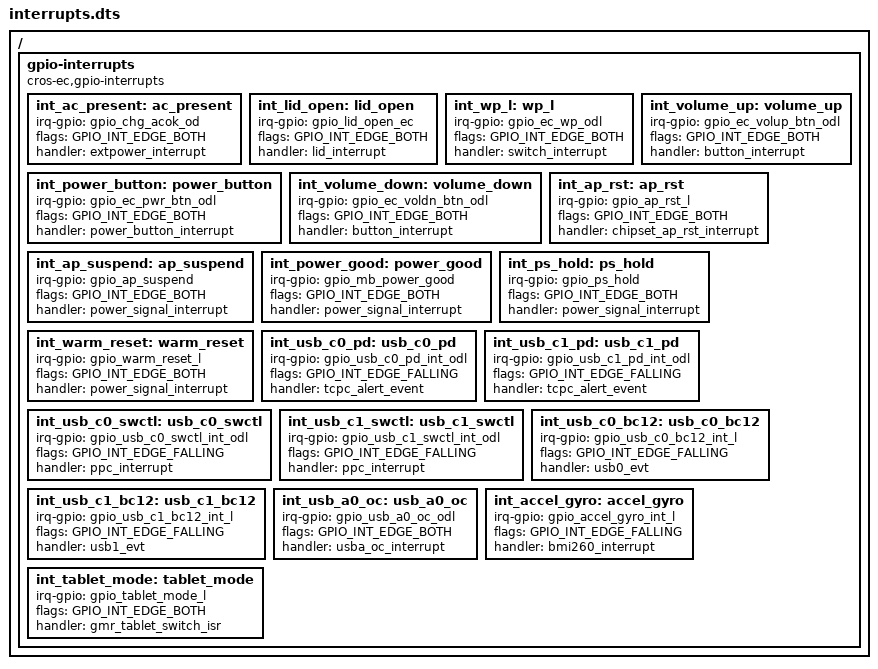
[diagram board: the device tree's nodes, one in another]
/* Copyright 2022 The Chromium OS Authors. All rights reserved.
 * Use of this source code is governed by a BSD-style license that can be
 * found in the LICENSE file.
 */

/ {
	gpio-interrupts {
		compatible = "cros-ec,gpio-interrupts";

		int_ac_present: ac_present {
			irq-gpio = <&gpio_chg_acok_od>;
			flags = <GPIO_INT_EDGE_BOTH>;
			handler = "extpower_interrupt";
		};
		int_lid_open: lid_open {
			irq-gpio = <&gpio_lid_open_ec>;
			flags = <GPIO_INT_EDGE_BOTH>;
			handler = "lid_interrupt";
		};
		int_wp_l: wp_l {
			irq-gpio = <&gpio_ec_wp_odl>;
			flags = <GPIO_INT_EDGE_BOTH>;
			handler = "switch_interrupt";
		};
		int_power_button: power_button {
			irq-gpio = <&gpio_ec_pwr_btn_odl>;
			flags = <GPIO_INT_EDGE_BOTH>;
			handler = "power_button_interrupt";
		};
		int_volume_up: volume_up {
			irq-gpio = <&gpio_ec_volup_btn_odl>;
			flags = <GPIO_INT_EDGE_BOTH>;
			handler = "button_interrupt";
		};
		int_volume_down: volume_down {
			irq-gpio = <&gpio_ec_voldn_btn_odl>;
			flags = <GPIO_INT_EDGE_BOTH>;
			handler = "button_interrupt";
		};
		int_ap_rst: ap_rst {
			irq-gpio = <&gpio_ap_rst_l>;
			flags = <GPIO_INT_EDGE_BOTH>;
			handler = "chipset_ap_rst_interrupt";
		};
		int_ap_suspend: ap_suspend {
			irq-gpio = <&gpio_ap_suspend>;
			flags = <GPIO_INT_EDGE_BOTH>;
			handler = "power_signal_interrupt";
		};
		int_power_good: power_good {
			irq-gpio = <&gpio_mb_power_good>;
			flags = <GPIO_INT_EDGE_BOTH>;
			handler = "power_signal_interrupt";
		};
		int_ps_hold: ps_hold {
			irq-gpio = <&gpio_ps_hold>;
			flags = <GPIO_INT_EDGE_BOTH>;
			handler = "power_signal_interrupt";
		};
		int_warm_reset: warm_reset {
			irq-gpio = <&gpio_warm_reset_l>;
			flags = <GPIO_INT_EDGE_BOTH>;
			handler = "power_signal_interrupt";
		};
		int_usb_c0_pd: usb_c0_pd {
			irq-gpio = <&gpio_usb_c0_pd_int_odl>;
			flags = <GPIO_INT_EDGE_FALLING>;
			handler = "tcpc_alert_event";
		};
		int_usb_c1_pd: usb_c1_pd {
			irq-gpio = <&gpio_usb_c1_pd_int_odl>;
			flags = <GPIO_INT_EDGE_FALLING>;
			handler = "tcpc_alert_event";
		};
		int_usb_c0_swctl: usb_c0_swctl {
			irq-gpio = <&gpio_usb_c0_swctl_int_odl>;
			flags = <GPIO_INT_EDGE_FALLING>;
			handler = "ppc_interrupt";
		};
		int_usb_c1_swctl: usb_c1_swctl {
			irq-gpio = <&gpio_usb_c1_swctl_int_odl>;
			flags = <GPIO_INT_EDGE_FALLING>;
			handler = "ppc_interrupt";
		};
		int_usb_c0_bc12: usb_c0_bc12 {
			irq-gpio = <&gpio_usb_c0_bc12_int_l>;
			flags = <GPIO_INT_EDGE_FALLING>;
			handler = "usb0_evt";
		};
		int_usb_c1_bc12: usb_c1_bc12 {
			irq-gpio = <&gpio_usb_c1_bc12_int_l>;
			flags = <GPIO_INT_EDGE_FALLING>;
			handler = "usb1_evt";
		};
		int_usb_a0_oc: usb_a0_oc {
			irq-gpio = <&gpio_usb_a0_oc_odl>;
			flags = <GPIO_INT_EDGE_BOTH>;
			handler = "usba_oc_interrupt";
		};
		int_accel_gyro: accel_gyro {
			irq-gpio = <&gpio_accel_gyro_int_l>;
			flags = <GPIO_INT_EDGE_FALLING>;
			handler = "bmi260_interrupt";
		};
		int_tablet_mode: tablet_mode {
			irq-gpio = <&gpio_tablet_mode_l>;
			flags = <GPIO_INT_EDGE_BOTH>;
			handler = "gmr_tablet_switch_isr";
		};
	};
};
